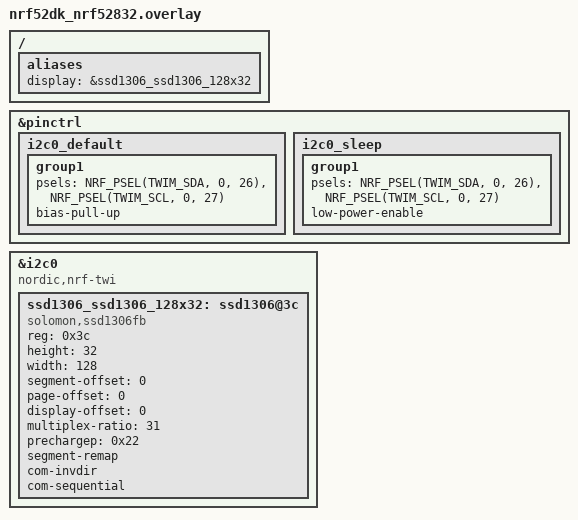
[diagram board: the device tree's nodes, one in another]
/*
 * Copyright (c) 2019 Callender-Consulting, LLC
 *
 * SPDX-License-Identifier: Apache-2.0
 */

&pinctrl {
    i2c0_default: i2c0_default {
        group1 {
            psels = <NRF_PSEL(TWIM_SDA,  0, 26)>,
                    <NRF_PSEL(TWIM_SCL,  0, 27)>;
            bias-pull-up;
        };
    };

    i2c0_sleep: i2c0_sleep {
        group1 {
            psels = <NRF_PSEL(TWIM_SDA,  0, 26)>,
                    <NRF_PSEL(TWIM_SCL,  0, 27)>;
            low-power-enable;
        };
    };
};

arduino_i2c: &i2c0 {
    compatible = "nordic,nrf-twi";
    status = "okay";

    ssd1306_ssd1306_128x32: ssd1306@3c {
        compatible = "solomon,ssd1306fb";
        reg = <0x3c>;
        height = <32>;
        width  = <128>;
        segment-offset  = <0>;
        page-offset     = <0>;
        display-offset  = <0>;
        multiplex-ratio = <31>;
        prechargep      = <0x22>;
        segment-remap;
        com-invdir;
        com-sequential;
    };
};

/ {
    aliases {
        display = &ssd1306_ssd1306_128x32;
    };
};
